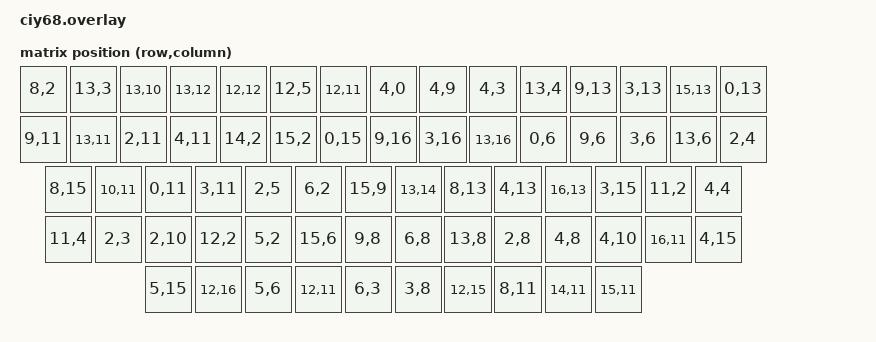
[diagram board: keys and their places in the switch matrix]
// This file was generated from a template. Edit it to match your keyboard.
// See https://zmk.dev/docs/development/hardware-integration/new-shield for more
// instructions.

#include <dt-bindings/zmk/matrix_transform.h>

// #include "ciy68-layouts.dtsi" // Para ZMK Studio

/ {
    chosen {
        zmk,physical-layout = &default_layout;
        zmk,battery = &vbatt;
    };

    kscan0: kscan0 {
        compatible = "zmk,kscan-gpio-charlieplex";
        wakeup-source;
        gpios
            = <&gpio0 6 GPIO_ACTIVE_HIGH>   // 0
            , <&gpio0 8 GPIO_ACTIVE_HIGH>   // 1
            , <&gpio0 17 GPIO_ACTIVE_HIGH>  // 2
            , <&gpio0 20 GPIO_ACTIVE_HIGH>  // 3
            , <&gpio0 22 GPIO_ACTIVE_HIGH>  // 4
            , <&gpio0 24 GPIO_ACTIVE_HIGH>  // 5
            , <&gpio1 0 GPIO_ACTIVE_HIGH>   // 6
            , <&gpio0 11 GPIO_ACTIVE_HIGH>  // 7
            , <&gpio1 4 GPIO_ACTIVE_HIGH>   // 8
            , <&gpio1 6 GPIO_ACTIVE_HIGH>   // 9
            , <&gpio0 10 GPIO_ACTIVE_HIGH>  // 10
            , <&gpio1 11 GPIO_ACTIVE_HIGH>  // 11
            , <&gpio1 13 GPIO_ACTIVE_HIGH>  // 12
            , <&gpio1 15 GPIO_ACTIVE_HIGH>  // 13
            , <&gpio0 2 GPIO_ACTIVE_HIGH>   // 14
            , <&gpio0 29 GPIO_ACTIVE_HIGH>  // 15
            , <&gpio0 31 GPIO_ACTIVE_HIGH>  // 16
//            , <&gpio1 1 GPIO_ACTIVE_HIGH>   // 17
//            , <&gpio1 2 GPIO_ACTIVE_HIGH>
//            , <&gpio1 7 GPIO_ACTIVE_HIGH>
            ;

//        interrupt-gpios = <&gpio0 9 (GPIO_ACTIVE_HIGH | GPIO_PULL_DOWN)>;
//        debounce-press-ms = 5; // Default is 5
//        debounce-release-ms = 5; // Default is 5
//        debounce-scan-period-ms = 1; // Default is 1
//        poll-period-ms = 10; // Default is 10

    };

    default_transform: default_transform {
        // See https://zmk.dev/docs/development/hardware-integration/new-shield#matrix-transform
        // for how to configure this
        compatible = "zmk,matrix-transform";
        columns = <18>;
        rows = <18>;

        map = <
RC(8,2) RC(13,3) RC(13,10) RC(13,12) RC(12,12) RC(12,5)RC(12,11) RC(4,0) RC(4,9) RC(4,3) RC(13,4)  RC(9,13) RC(3,13)    RC(15,13) RC(0,13)
RC(9,11)   RC(13,11) RC(2,11) RC(4,11) RC(14,2) RC(15,2) RC(0,15) RC(9,16) RC(3,16) RC(13,16) RC(0,6) RC(9,6) RC(3,6)   RC(13,6)  RC(2,4)
RC(8,15)     RC(10,11) RC(0,11) RC(3,11) RC(2,5) RC(6,2) RC(15,9) RC(13,14) RC(8,13) RC(4,13) RC(16,13) RC(3,15)        RC(11,2)  RC(4,4)
RC(11,4)       RC(2,3) RC(2,10) RC(12,2) RC(5,2) RC(15,6) RC(9,8) RC(6,8) RC(13,8) RC(2,8)    RC(4,8)   RC(4,10)        RC(16,11) RC(4,15)
RC(5,15)   RC(12,16)   RC(5,6)                RC(12,11)                  RC(6,3)   RC(3,8)   RC(12,15)  RC(8,11)        RC(14,11) RC(15,11)
        >;
    };
    
    default_layout: default_layout {
        transform = <&default_transform>;
        compatible = "zmk,physical-layout";
        display-name = "Default";
        /* If you use ZMK Studio / physical layouts, add the required properties here.
         * The key point for the build failure is that the label exists.
         */
    };

    vbatt: vbatt {
        compatible = "zmk,battery-nrf-vddh";
    };
};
